AUTOSAR XML (schema 4-0-3)
standard types defined: uint8, uint16, sint16
package /SystemComponents
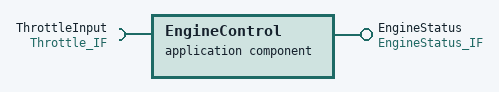
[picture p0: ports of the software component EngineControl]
  application sw component type EngineControl
    provide port EngineStatus: provided-interface=EngineStatus_IF
    require port ThrottleInput: required-interface=Throttle_IF
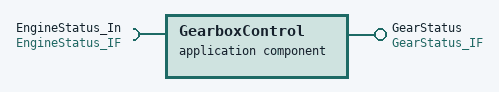
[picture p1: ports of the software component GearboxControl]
  application sw component type GearboxControl
    require port EngineStatus_In: required-interface=EngineStatus_IF
    provide port GearStatus: provided-interface=GearStatus_IF
  composition sw component type PowertrainSystem
    component engineCtrl: type=EngineControl
    component gearboxCtrl: type=GearboxControl
    connect engineCtrl.EngineStatus -> gearboxCtrl.EngineStatus_In
  sender receiver interface EngineStatus_IF
    data rpm: type=uint16
    data temperature: type=sint16
  sender receiver interface Throttle_IF
    data position: type=uint8
  sender receiver interface GearStatus_IF
    data currentGear: type=uint8
  ecu EngineECU: ecu-configuration={ecu=EngineECU, ecu-extract=PowertrainSystem}
